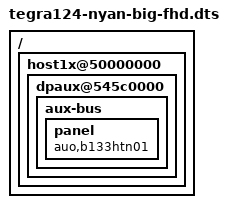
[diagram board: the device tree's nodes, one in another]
// SPDX-License-Identifier: GPL-2.0
/dts-v1/;

#include "tegra124-nyan-big.dts"

/ {
	/* Version of Nyan Big with 1080p panel */
	host1x@50000000 {
		dpaux@545c0000 {
			aux-bus {
				panel: panel {
					compatible = "auo,b133htn01";
				};
			};
		};
	};
};
